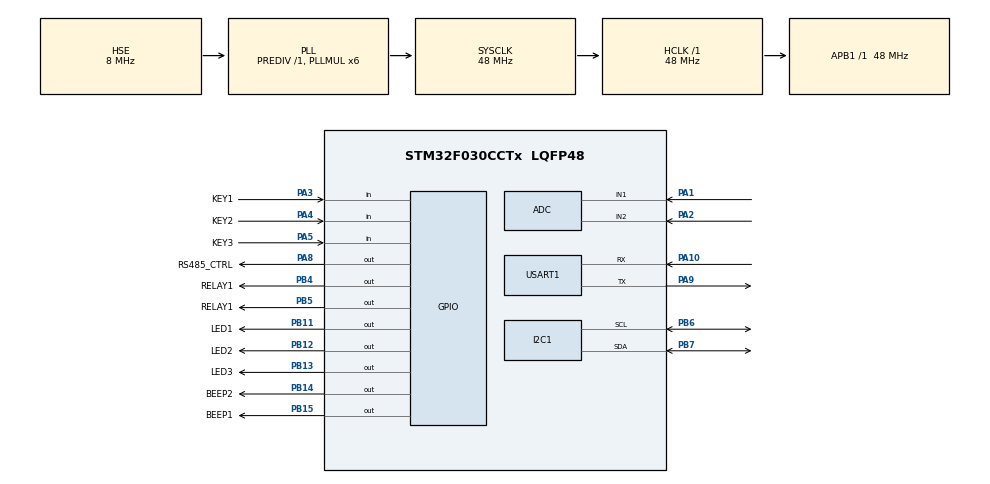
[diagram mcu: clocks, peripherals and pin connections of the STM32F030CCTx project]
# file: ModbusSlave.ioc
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Dma.I2C1_RX.2.Direction=DMA_PERIPH_TO_MEMORY
Dma.I2C1_RX.2.Instance=DMA1_Channel3
Dma.I2C1_RX.2.MemDataAlignment=DMA_MDATAALIGN_BYTE
Dma.I2C1_RX.2.MemInc=DMA_MINC_ENABLE
Dma.I2C1_RX.2.Mode=DMA_NORMAL
Dma.I2C1_RX.2.PeriphDataAlignment=DMA_PDATAALIGN_BYTE
Dma.I2C1_RX.2.PeriphInc=DMA_PINC_DISABLE
Dma.I2C1_RX.2.Priority=DMA_PRIORITY_LOW
Dma.I2C1_TX.3.Direction=DMA_MEMORY_TO_PERIPH
Dma.I2C1_TX.3.Instance=DMA1_Channel2
Dma.I2C1_TX.3.MemDataAlignment=DMA_MDATAALIGN_BYTE
Dma.I2C1_TX.3.MemInc=DMA_MINC_ENABLE
Dma.I2C1_TX.3.Mode=DMA_NORMAL
Dma.I2C1_TX.3.PeriphDataAlignment=DMA_PDATAALIGN_BYTE
Dma.I2C1_TX.3.PeriphInc=DMA_PINC_DISABLE
Dma.I2C1_TX.3.Priority=DMA_PRIORITY_LOW
Dma.Request0=USART1_RX
Dma.Request1=USART1_TX
Dma.Request2=I2C1_RX
Dma.Request3=I2C1_TX
Dma.USART1_RX.0.Direction=DMA_PERIPH_TO_MEMORY
Dma.USART1_RX.0.Instance=DMA1_Channel1
Dma.USART1_RX.0.MemDataAlignment=DMA_MDATAALIGN_BYTE
Dma.USART1_RX.0.MemInc=DMA_MINC_ENABLE
Dma.USART1_RX.0.Mode=DMA_NORMAL
Dma.USART1_RX.0.PeriphDataAlignment=DMA_PDATAALIGN_BYTE
Dma.USART1_RX.0.PeriphInc=DMA_PINC_DISABLE
Dma.USART1_RX.0.Priority=DMA_PRIORITY_LOW
Dma.USART1_TX.1.Direction=DMA_MEMORY_TO_PERIPH
Dma.USART1_TX.1.Instance=DMA1_Channel4
Dma.USART1_TX.1.MemDataAlignment=DMA_MDATAALIGN_BYTE
Dma.USART1_TX.1.MemInc=DMA_MINC_ENABLE
Dma.USART1_TX.1.Mode=DMA_NORMAL
Dma.USART1_TX.1.PeriphDataAlignment=DMA_PDATAALIGN_BYTE
Dma.USART1_TX.1.PeriphInc=DMA_PINC_DISABLE
Dma.USART1_TX.1.Priority=DMA_PRIORITY_LOW
I2C1.Timing=0x00201D2B
Mcu.Family=STM32F0
Mcu.Name=STM32F030CCTx
Mcu.Package=LQFP48
NVIC.DMA1_Channel1_IRQn=true\:3\:0\:true\:false\:true\:false\:true\:true
NVIC.DMA1_Channel2_3_IRQn=true\:3\:0\:true\:false\:true\:false\:true\:true
NVIC.DMA1_Channel4_5_IRQn=true\:3\:0\:true\:false\:true\:false\:true\:true
NVIC.I2C1_IRQn=true\:3\:0\:true\:false\:true\:true\:true\:true
NVIC.TIM3_IRQn=true\:0\:0\:true\:false\:false\:true\:true\:true
NVIC.TIM7_IRQn=true\:3\:0\:false\:false\:true\:false\:true\:true
NVIC.TimeBase=TIM7_IRQn
NVIC.TimeBaseIP=TIM7
NVIC.USART1_IRQn=true\:1\:0\:true\:false\:false\:true\:true\:true
PA1.Mode=IN1
PA1.Signal=ADC_IN1
PA10.Mode=Asynchronous
PA10.Signal=USART1_RX
PA13.Mode=Serial_Wire
PA13.Signal=SYS_SWDIO
PA14.Mode=Serial_Wire
PA14.Signal=SYS_SWCLK
PA2.Mode=IN2
PA2.Signal=ADC_IN2
PA3.GPIO_Label=KEY1
PA3.GPIO_PuPd=GPIO_PULLUP
PA3.Signal=GPIO_Input
PA4.GPIO_Label=KEY2
PA4.GPIO_PuPd=GPIO_PULLUP
PA4.Signal=GPIO_Input
PA5.GPIO_Label=KEY3
PA5.Signal=GPIO_Input
PA8.GPIO_Label=RS485_CTRL
PA8.Signal=GPIO_Output
PA9.Mode=Asynchronous
PA9.Signal=USART1_TX
PB11.GPIO_Label=LED1
PB11.Signal=GPIO_Output
PB12.GPIO_Label=LED2
PB12.Signal=GPIO_Output
PB13.GPIO_Label=LED3
PB13.Signal=GPIO_Output
PB14.GPIO_Label=BEEP2
PB14.Signal=GPIO_Output
PB15.GPIO_Label=BEEP1
PB15.Signal=GPIO_Output
PB4.GPIO_Label=RELAY1
PB4.Signal=GPIO_Output
PB5.GPIO_Label=RELAY1
PB5.Signal=GPIO_Output
PB6.Mode=I2C
PB6.Signal=I2C1_SCL
PB7.Mode=I2C
PB7.Signal=I2C1_SDA
PF0-OSC_IN.Mode=HSE-External-Oscillator
PF0-OSC_IN.Signal=RCC_OSC_IN
PF1-OSC_OUT.Mode=HSE-External-Oscillator
PF1-OSC_OUT.Signal=RCC_OSC_OUT
ProjectManager.HeapSize=0x200
ProjectManager.StackSize=0x400
ProjectManager.TargetToolchain=MDK-ARM V5.32
RCC.AHBFreq_Value=48000000
RCC.APB1Freq_Value=48000000
RCC.APB1TimFreq_Value=48000000
RCC.HCLKFreq_Value=48000000
RCC.PLLMUL=RCC_PLL_MUL6
RCC.PLLSourceVirtual=RCC_PLLSOURCE_HSE
RCC.SYSCLKFreq_VALUE=48000000
RCC.SYSCLKSource=RCC_SYSCLKSOURCE_PLLCLK
USART1.VirtualMode-Asynchronous=VM_ASYNC
VP_SYS_VS_tim7.Mode=TIM7
VP_TIM3_VS_ClockSourceINT.Mode=Internal
board=custom

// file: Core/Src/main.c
/* USER CODE BEGIN Header */
/**
  ******************************************************************************
  * @file           : main.c
  * @brief          : Main program body
  ******************************************************************************
  * @attention
  *
  * Copyright (c) 2026 STMicroelectronics.
  * All rights reserved.
  *
  * This software is licensed under terms that can be found in the LICENSE file
  * in the root directory of this software component.
  * If no LICENSE file comes with this software, it is provided AS-IS.
  *
  ******************************************************************************
  */
/* USER CODE END Header */
#include "main.h"
#include "adc.h"
#include "dma.h"
#include "i2c.h"
#include "tim.h"
#include "usart.h"
#include "gpio.h"

/* USER CODE BEGIN Includes */
#include "app_task.h"
#include "./driver_systick/driver_systick.h"
#include "./driver_ah20/driver_ah20.h"
#include "./driver_adc/driver_adc.h"
/* USER CODE END Includes */

void SystemClock_Config(void);

int main(void)
{

  /* MCU Configuration--------------------------------------------------------*/

  /* Reset of all peripherals, Initializes the Flash interface and the Systick. */
  HAL_Init();

  /* Configure the system clock */
  SystemClock_Config();

  /* Initialize all configured peripherals */
  MX_GPIO_Init();
  MX_DMA_Init();
  MX_ADC_Init();
  MX_USART1_UART_Init();
  MX_I2C1_Init();
  MX_TIM3_Init();
  /* USER CODE BEGIN 2 */
  SysTickInit();
  AHT20DriverInitial();
  ADCDriverInit();
  AppTaskInit();
  /* USER CODE END 2 */

  /* Infinite loop */
  /* USER CODE BEGIN WHILE */
  while (1)
  {
    AppTaskLoop();
    /* USER CODE END WHILE */

  }
}

void SystemClock_Config(void)
{
  RCC_OscInitTypeDef RCC_OscInitStruct = {0};
  RCC_ClkInitTypeDef RCC_ClkInitStruct = {0};
  RCC_PeriphCLKInitTypeDef PeriphClkInit = {0};

  /** Initializes the RCC Oscillators according to the specified parameters
  * in the RCC_OscInitTypeDef structure.
  */
  RCC_OscInitStruct.OscillatorType = RCC_OSCILLATORTYPE_HSI|RCC_OSCILLATORTYPE_HSI14
                              |RCC_OSCILLATORTYPE_HSE;
  RCC_OscInitStruct.HSEState = RCC_HSE_ON;
  RCC_OscInitStruct.HSIState = RCC_HSI_ON;
  RCC_OscInitStruct.HSI14State = RCC_HSI14_ON;
  RCC_OscInitStruct.HSICalibrationValue = RCC_HSICALIBRATION_DEFAULT;
  RCC_OscInitStruct.HSI14CalibrationValue = 16;
  RCC_OscInitStruct.PLL.PLLState = RCC_PLL_ON;
  RCC_OscInitStruct.PLL.PLLSource = RCC_PLLSOURCE_HSE;
  RCC_OscInitStruct.PLL.PLLMUL = RCC_PLL_MUL6;
  RCC_OscInitStruct.PLL.PREDIV = RCC_PREDIV_DIV1;
  if (HAL_RCC_OscConfig(&RCC_OscInitStruct) != HAL_OK)
  {
    Error_Handler();
  }

  /** Initializes the CPU, AHB and APB buses clocks
  */
  RCC_ClkInitStruct.ClockType = RCC_CLOCKTYPE_HCLK|RCC_CLOCKTYPE_SYSCLK
                              |RCC_CLOCKTYPE_PCLK1;
  RCC_ClkInitStruct.SYSCLKSource = RCC_SYSCLKSOURCE_PLLCLK;
  RCC_ClkInitStruct.AHBCLKDivider = RCC_SYSCLK_DIV1;
  RCC_ClkInitStruct.APB1CLKDivider = RCC_HCLK_DIV1;

  if (HAL_RCC_ClockConfig(&RCC_ClkInitStruct, FLASH_LATENCY_1) != HAL_OK)
  {
    Error_Handler();
  }
  PeriphClkInit.PeriphClockSelection = RCC_PERIPHCLK_USART1|RCC_PERIPHCLK_I2C1;
  PeriphClkInit.Usart1ClockSelection = RCC_USART1CLKSOURCE_PCLK1;
  PeriphClkInit.I2c1ClockSelection = RCC_I2C1CLKSOURCE_HSI;
  if (HAL_RCCEx_PeriphCLKConfig(&PeriphClkInit) != HAL_OK)
  {
    Error_Handler();
  }
}

void HAL_TIM_PeriodElapsedCallback(TIM_HandleTypeDef *htim)
{
  if (htim->Instance == TIM7)
  {
    HAL_IncTick();
  }
}

void Error_Handler(void)
{
  __disable_irq();
  while (1)
  {
  }
}
